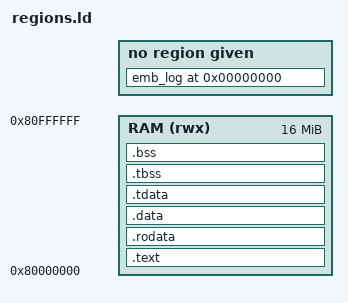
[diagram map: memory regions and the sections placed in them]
/* SPDX-License-Identifier: Apache-2.0 */
/*
 * This file is part of EmbLinkRTOS, a deterministic real-time kernel for microcontrollers.
 * Licensed under the Apache License, Version 2.0; see the LICENSE file at the repository root.
 */

/**
 * @file    regions.ld
 * @brief   Linker script for riscv32_virt (qemu-virt-rv32): the image is loaded into RAM and runs
 *          there, so .data needs no copy. The kernel's registration tables are bracketed by name
 *          (SPEC-001 §6.4, HW-006).
 *
 * @details
 * Generated by emb-hwgen 0.1.0, schema v0. Do not edit: change the
 * description and run hw/gen/emb-hwgen.py generate --board boards/qemu/riscv32_virt (HW-003).
 * Inputs (SHA-256):
 *   arch/riscv/arch.yaml
 *     576dcfbd779175e106541ceedf44ba0df15b587b69693ca081dd38f621c3b5b5
 *   boards/qemu/riscv32_virt/board.yaml
 *     dd10248b11a98ff1151ee275d2b5a38a035d49fe7a826c70b8613462fd752d78
 *   soc/qemu/virt/rv32.yaml
 *     b183443809cef1f71a7ce0e8d99e5ffe0881a4137546405b60886364bd93aa7f
 */
OUTPUT_ARCH(riscv)
ENTRY(embn_rv_reset)

MEMORY
{
  RAM (rwx) : ORIGIN = 0x80000000, LENGTH = 16M
}

SECTIONS
{
  .text : {
    KEEP(*(.text.embn_rv_reset))
    *(.text .text.*)
  } > RAM

  .rodata : ALIGN(16) {
    *(.rodata .rodata.* .srodata .srodata.*)
    . = ALIGN(16); /* the table entries' own alignment (sizeof(void *) * 4) */
    __start_emb_init_table = .;
    KEEP(*(emb_init_table))
    __stop_emb_init_table = .;
    . = ALIGN(16);
    __start_emb_test_table = .;
    KEEP(*(emb_test_table))
    __stop_emb_test_table = .;
  } > RAM

  .data : ALIGN(16) {
    *(.data .data.* .sdata .sdata.*)
    /* the GOT, which LLD makes for Clang's medany code: an undefined weak symbol may be 0,
       out of auipc's reach, so Clang loads the table bounds' addresses from it */
    *(.got .got.*)
  } > RAM

  /* the C library's thread-local block (errno in picolibc), one for every thread: .tdata in
     place, .tbss reserved after it, which the reset clears; tp points at it (A88) */
  /* rv_switch.S puts a word in each, so both exist and the TLS segment starts at .tdata */
  .tdata : ALIGN(16) { KEEP(*(.tdata.emb_tls_anchor)) *(.tdata .tdata.* .gnu.linkonce.td.*) } > RAM
  .tbss : { KEEP(*(.tbss.emb_tls_anchor)) *(.tbss .tbss.* .gnu.linkonce.tb.* .tcommon) } > RAM
  __emb_tls_start = ADDR(.tdata);
  __emb_tbss_start = ADDR(.tdata) + SIZEOF(.tdata);
  __emb_tls_end = ADDR(.tbss) + SIZEOF(.tbss);

  /* placed past .tbss, which takes no room of its own */
  .bss ALIGN(__emb_tls_end, 16) (NOLOAD) : {
    __bss_start = .;
    *(.bss .bss.* .sbss .sbss.* COMMON)
    . = ALIGN(16);
    __bss_end = .;
  } > RAM

  end = .;
  /* the crash record's memory (SPEC-015 §4, A73): above the stack and outside every loaded
     segment, so neither startup nor a loader's reset clears it */
  __emb_retained_end = ORIGIN(RAM) + LENGTH(RAM);
  __emb_retained_start = __emb_retained_end - 192;
  /* below it, 32 bytes the test framework keeps across the resets of its fault checks (A89) */
  __emb_test_retained_end = __emb_retained_start;
  __emb_test_retained_start = __emb_test_retained_end - 32;
  __stack_top = __emb_test_retained_start;

  /* the log's call sites (A127): kept in the ELF for tools/logdec and out of the image. At
     address 0, from which a record's identifier is its metadata's offset plus 8; the first 8
     bytes stay empty, so no metadata is at address 0, the null pointer. Last, since setting
     its address moves the location counter. */
  emb_log 0 (INFO) : {
    __start_emb_log = .;
    . += 8;
    KEEP(*(emb_log))
    __stop_emb_log = .;
  }
}
